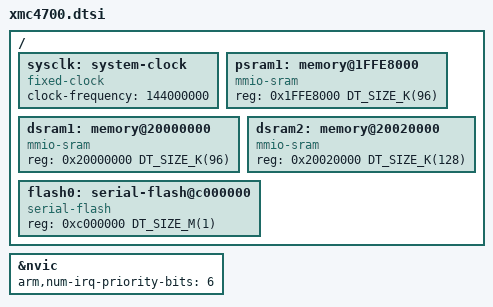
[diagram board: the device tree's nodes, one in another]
/*
 * Copyright (c) 2020 Linumiz
 * Author: Parthiban Nallathambi <parthiban@linumiz.com>
 *
 * SPDX-License-Identifier: Apache-2.0
 */

#include <mem.h>
#include <infineon/xmc4xxx.dtsi>

/ {
	sysclk: system-clock {
		compatible = "fixed-clock";
		clock-frequency = <144000000>;
		#clock-cells = <0>;
	};
	
	/* TODO: Add psram1 & dsram2 to MEMORY layout of linker */
	psram1: memory@1FFE8000 {
		compatible = "mmio-sram";
	};

	dsram1: memory@20000000 {
		compatible = "mmio-sram";
	};

	dsram2: memory@20020000 {
		compatible = "mmio-sram";
	};

	flash0: serial-flash@c000000 {
		compatible = "serial-flash";
	};

};

&nvic {
	arm,num-irq-priority-bits = <6>;
};

&psram1 {
	reg = <0x1FFE8000 DT_SIZE_K(96)>;
};

&dsram1 {
	reg = <0x20000000 DT_SIZE_K(96)>;
};

&dsram2 {
	reg = <0x20020000 DT_SIZE_K(128)>;
};

&flash0 {
	reg = <0xc000000 DT_SIZE_M(1)>;
};
